# ATSAMV71Q21 register map
Vendor: Microchip Technology; Series: SAMV71; File version: 0
CPU: CM7 r1p1, little endian, MPU, FPU, 3 interrupt priority bits
Registers are 32-bit, access not given, no defined reset value unless marked. A register's access mark holds for its fields unless they carry their own. Offsets are from the block's base; [hi:lo] are bit positions.

## TWIHS0 — Two-wire Interface High Speed
Base 0x40018000; register names take the prefix TWIHS_
Same registers: TWIHS1 0x4001C000, TWIHS2 0x40060000
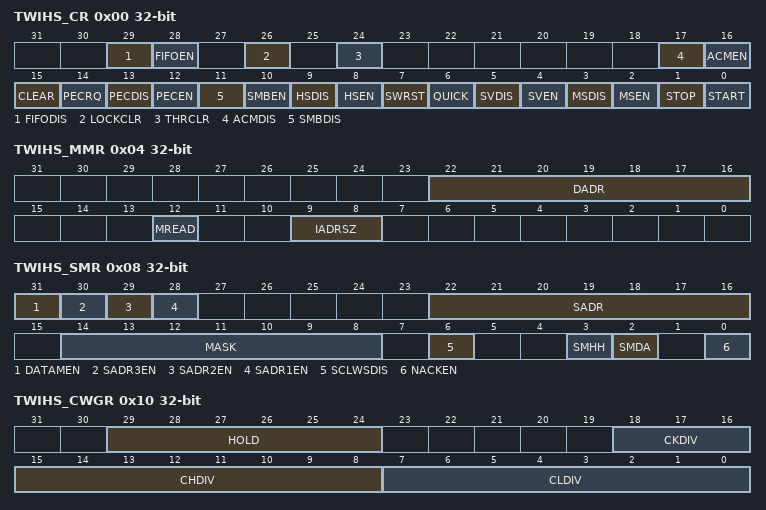
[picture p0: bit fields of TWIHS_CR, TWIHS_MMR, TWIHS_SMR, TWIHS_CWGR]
0x00 TWIHS_CR wo — Control Register
  [29] FIFODIS — FIFO Disable
  [28] FIFOEN — FIFO Enable
  [26] LOCKCLR — Lock Clear
  [24] THRCLR — Transmit Holding Register Clear
  [17] ACMDIS — Alternative Command Mode Disable
  [16] ACMEN — Alternative Command Mode Enable
  [15] CLEAR — Bus CLEAR Command
  [14] PECRQ — PEC Request
  [13] PECDIS — Packet Error Checking Disable
  [12] PECEN — Packet Error Checking Enable
  [11] SMBDIS — SMBus Mode Disabled
  [10] SMBEN — SMBus Mode Enabled
  [9] HSDIS — TWIHS High-Speed Mode Disabled
  [8] HSEN — TWIHS High-Speed Mode Enabled
  [7] SWRST — Software Reset
  [6] QUICK — SMBus Quick Command
  [5] SVDIS — TWIHS Slave Mode Disabled
  [4] SVEN — TWIHS Slave Mode Enabled
  [3] MSDIS — TWIHS Master Mode Disabled
  [2] MSEN — TWIHS Master Mode Enabled
  [1] STOP — Send a STOP Condition
  [0] START — Send a START Condition
0x04 TWIHS_MMR — Master Mode Register
  [22:16] DADR — Device Address
  [12] MREAD — Master Read Direction
  [9:8] IADRSZ — Internal Device Address Size
    0=NONE (No internal device address); 1=_1_BYTE (One-byte internal device address); 2=_2_BYTE (Two-byte internal device address); 3=_3_BYTE (Three-byte internal device address)
0x08 TWIHS_SMR — Slave Mode Register
  [31] DATAMEN — Data Matching Enable
  [30] SADR3EN — Slave Address 3 Enable
  [29] SADR2EN — Slave Address 2 Enable
  [28] SADR1EN — Slave Address 1 Enable
  [22:16] SADR — Slave Address
  [14:8] MASK — Slave Address Mask
  [6] SCLWSDIS — Clock Wait State Disable
  [3] SMHH — SMBus Host Header
  [2] SMDA — SMBus Default Address
  [0] NACKEN — Slave Receiver Data Phase NACK enable
0x0C TWIHS_IADR — Internal Address Register
  [23:0] IADR — Internal Address
0x10 TWIHS_CWGR — Clock Waveform Generator Register
  [29:24] HOLD — TWD Hold Time Versus TWCK Falling
  [18:16] CKDIV — Clock Divider
  [15:8] CHDIV — Clock High Divider
  [7:0] CLDIV — Clock Low Divider
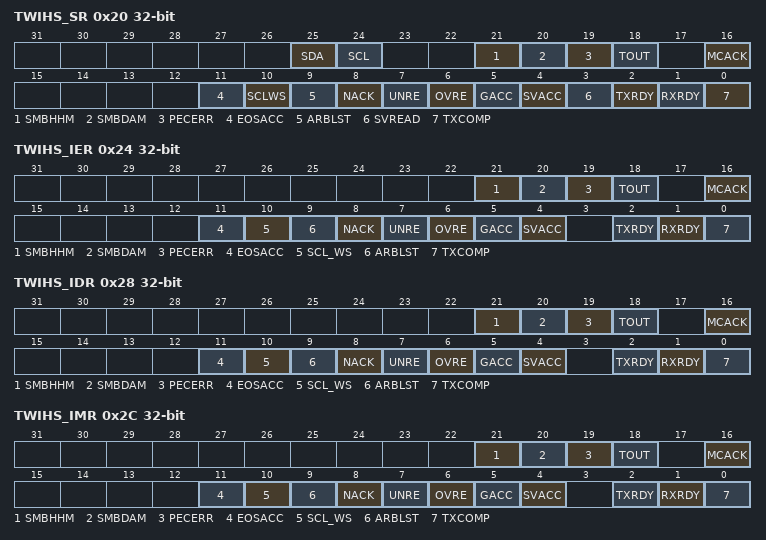
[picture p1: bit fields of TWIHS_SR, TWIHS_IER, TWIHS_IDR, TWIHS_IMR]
0x20 TWIHS_SR ro — Status Register
  [25] SDA — SDA Line Value
  [24] SCL — SCL Line Value
  [21] SMBHHM — SMBus Host Header Address Match (cleared on read)
  [20] SMBDAM — SMBus Default Address Match (cleared on read)
  [19] PECERR — PEC Error (cleared on read)
  [18] TOUT — Timeout Error (cleared on read)
  [16] MCACK — Master Code Acknowledge (cleared on read)
  [11] EOSACC — End Of Slave Access (cleared on read)
  [10] SCLWS — Clock Wait State
  [9] ARBLST — Arbitration Lost (cleared on read)
  [8] NACK — Not Acknowledged (cleared on read)
  [7] UNRE — Underrun Error (cleared on read)
  [6] OVRE — Overrun Error (cleared on read)
  [5] GACC — General Call Access (cleared on read)
  [4] SVACC — Slave Access
  [3] SVREAD — Slave Read
  [2] TXRDY — Transmit Holding Register Ready (cleared by writing TWIHS_THR)
  [1] RXRDY — Receive Holding Register Ready (cleared by reading TWIHS_RHR)
  [0] TXCOMP — Transmission Completed (cleared by writing TWIHS_THR)
0x24 TWIHS_IER wo — Interrupt Enable Register
  [21] SMBHHM — SMBus Host Header Address Match Interrupt Enable
  [20] SMBDAM — SMBus Default Address Match Interrupt Enable
  [19] PECERR — PEC Error Interrupt Enable
  [18] TOUT — Timeout Error Interrupt Enable
  [16] MCACK — Master Code Acknowledge Interrupt Enable
  [11] EOSACC — End Of Slave Access Interrupt Enable
  [10] SCL_WS — Clock Wait State Interrupt Enable
  [9] ARBLST — Arbitration Lost Interrupt Enable
  [8] NACK — Not Acknowledge Interrupt Enable
  [7] UNRE — Underrun Error Interrupt Enable
  [6] OVRE — Overrun Error Interrupt Enable
  [5] GACC — General Call Access Interrupt Enable
  [4] SVACC — Slave Access Interrupt Enable
  [2] TXRDY — Transmit Holding Register Ready Interrupt Enable
  [1] RXRDY — Receive Holding Register Ready Interrupt Enable
  [0] TXCOMP — Transmission Completed Interrupt Enable
0x28 TWIHS_IDR wo — Interrupt Disable Register
  [21] SMBHHM — SMBus Host Header Address Match Interrupt Disable
  [20] SMBDAM — SMBus Default Address Match Interrupt Disable
  [19] PECERR — PEC Error Interrupt Disable
  [18] TOUT — Timeout Error Interrupt Disable
  [16] MCACK — Master Code Acknowledge Interrupt Disable
  [11] EOSACC — End Of Slave Access Interrupt Disable
  [10] SCL_WS — Clock Wait State Interrupt Disable
  [9] ARBLST — Arbitration Lost Interrupt Disable
  [8] NACK — Not Acknowledge Interrupt Disable
  [7] UNRE — Underrun Error Interrupt Disable
  [6] OVRE — Overrun Error Interrupt Disable
  [5] GACC — General Call Access Interrupt Disable
  [4] SVACC — Slave Access Interrupt Disable
  [2] TXRDY — Transmit Holding Register Ready Interrupt Disable
  [1] RXRDY — Receive Holding Register Ready Interrupt Disable
  [0] TXCOMP — Transmission Completed Interrupt Disable
0x2C TWIHS_IMR ro — Interrupt Mask Register
  [21] SMBHHM — SMBus Host Header Address Match Interrupt Mask
  [20] SMBDAM — SMBus Default Address Match Interrupt Mask
  [19] PECERR — PEC Error Interrupt Mask
  [18] TOUT — Timeout Error Interrupt Mask
  [16] MCACK — Master Code Acknowledge Interrupt Mask
  [11] EOSACC — End Of Slave Access Interrupt Mask
  [10] SCL_WS — Clock Wait State Interrupt Mask
  [9] ARBLST — Arbitration Lost Interrupt Mask
  [8] NACK — Not Acknowledge Interrupt Mask
  [7] UNRE — Underrun Error Interrupt Mask
  [6] OVRE — Overrun Error Interrupt Mask
  [5] GACC — General Call Access Interrupt Mask
  [4] SVACC — Slave Access Interrupt Mask
  [2] TXRDY — Transmit Holding Register Ready Interrupt Mask
  [1] RXRDY — Receive Holding Register Ready Interrupt Mask
  [0] TXCOMP — Transmission Completed Interrupt Mask
0x30 TWIHS_RHR ro — Receive Holding Register
  [7:0] RXDATA — Master or Slave Receive Holding Data
0x34 TWIHS_THR wo — Transmit Holding Register
  [7:0] TXDATA — Master or Slave Transmit Holding Data
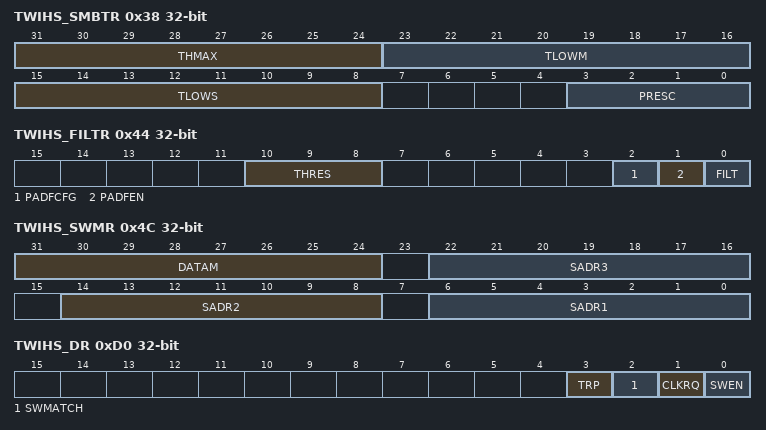
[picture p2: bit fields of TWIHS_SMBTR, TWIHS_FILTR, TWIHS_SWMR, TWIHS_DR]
0x38 TWIHS_SMBTR — SMBus Timing Register
  [31:24] THMAX — Clock High Maximum Cycles
  [23:16] TLOWM — Master Clock Stretch Maximum Cycles
  [15:8] TLOWS — Slave Clock Stretch Maximum Cycles
  [3:0] PRESC — SMBus Clock Prescaler
0x44 TWIHS_FILTR — Filter Register
  [10:8] THRES — Digital Filter Threshold
  [2] PADFCFG — PAD Filter Config
  [1] PADFEN — PAD Filter Enable
  [0] FILT — RX Digital Filter
0x4C TWIHS_SWMR — SleepWalking Matching Register
  [31:24] DATAM — Data Match
  [22:16] SADR3 — Slave Address 3
  [14:8] SADR2 — Slave Address 2
  [6:0] SADR1 — Slave Address 1
0xD0 TWIHS_DR ro — Debug Register
  [3] TRP — Transfer Pending
  [2] SWMATCH — SleepWalking Match
  [1] CLKRQ — Clock Request
  [0] SWEN — SleepWalking Enable
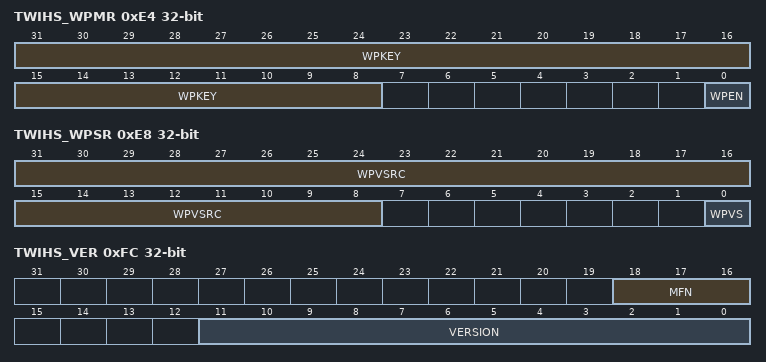
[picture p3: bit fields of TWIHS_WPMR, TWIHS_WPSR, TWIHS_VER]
0xE4 TWIHS_WPMR — Write Protection Mode Register
  [31:8] WPKEY — Write Protection Key
    0x545749=PASSWD (Writing any other value in this field aborts the write operation of the WPEN bit.Always reads as 0)
  [0] WPEN — Write Protection Enable
0xE8 TWIHS_WPSR ro — Write Protection Status Register
  [31:8] WPVSRC — Write Protection Violation Source
  [0] WPVS — Write Protection Violation Status
0xFC TWIHS_VER ro — Version Register
  [18:16] MFN — Metal Fix Number
  [11:0] VERSION — Version of the Hardware Module
